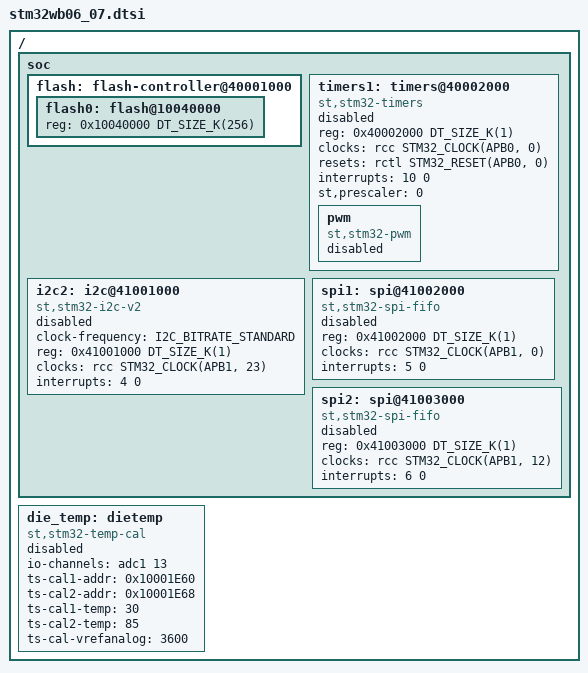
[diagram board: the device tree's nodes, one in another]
/*
 * Copyright (c) 2024 STMicroelectronics
 *
 * SPDX-License-Identifier: Apache-2.0
 */

#include <st/wb0/stm32wb0.dtsi>

/* Common Device Tree fragment for STM32WB06 and STM32WB07
 *
 * STM32WB06 and STM32WB07 are mostly identical. The only difference
 * is RAM size, which is defined in the SoC-specific DTS fragments.
 */
/ {
	soc {
		flash: flash-controller@40001000 {
			flash0: flash@10040000 {
				reg = <0x10040000 DT_SIZE_K(256)>;
			};
		};

		timers1: timers@40002000 {
			compatible = "st,stm32-timers";
			reg = <0x40002000 DT_SIZE_K(1)>;
			clocks = <&rcc STM32_CLOCK(APB0, 0)>;
			resets = <&rctl STM32_RESET(APB0, 0)>;
			interrupts = <10 0>;
			interrupt-names = "global";
			st,prescaler = <0>;
			status = "disabled";

			pwm {
				compatible = "st,stm32-pwm";
				status = "disabled";
				#pwm-cells = <3>;
			};
		};

		i2c2: i2c@41001000 {
			compatible = "st,stm32-i2c-v2";
			clock-frequency = <I2C_BITRATE_STANDARD>; //TODO: is this good?
			#address-cells = <1>;
			#size-cells = <0>;
			reg = <0x41001000 DT_SIZE_K(1)>;
			clocks = <&rcc STM32_CLOCK(APB1, 23)>;
			interrupts = <4 0>;
			interrupt-names = "combined";
			status = "disabled";
		};

		spi1: spi@41002000 {
			compatible = "st,stm32-spi-fifo", "st,stm32-spi";
			#address-cells = <1>;
			#size-cells = <0>;
			reg = <0x41002000 DT_SIZE_K(1)>;
			clocks = <&rcc STM32_CLOCK(APB1, 0)>;
			interrupts = <5 0>;
			status = "disabled";
		};

		spi2: spi@41003000 {
			compatible = "st,stm32-spi-fifo", "st,stm32-spi";
			#address-cells = <1>;
			#size-cells = <0>;
			reg = <0x41003000 DT_SIZE_K(1)>;
			clocks = <&rcc STM32_CLOCK(APB1, 12)>;
			interrupts = <6 0>;
			status = "disabled";

			//TODO: create the I2S node corresponding to spi2
		};
	};

	die_temp: dietemp {
		compatible = "st,stm32-temp-cal";
		io-channels = <&adc1 13>;
		ts-cal1-addr = <0x10001E60>;
		ts-cal2-addr = <0x10001E68>;
		ts-cal1-temp = <30>;
		ts-cal2-temp = <85>;
		/* dietemp driver is oblivious to WB0x ADC specificities.
		 * This value must be equal to ADC driver `ref_internal`.
		 */
		ts-cal-vrefanalog = <3600>;
		status = "disabled";
	};
};
